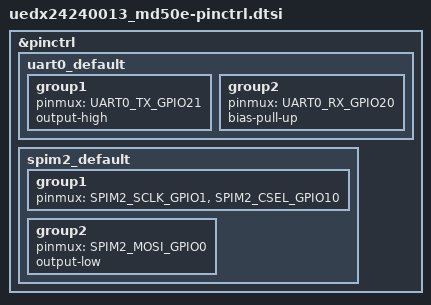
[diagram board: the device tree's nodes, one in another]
/*
 * Copyright (c) 2024 Espressif Systems (Shanghai) Co., Ltd.
 * Copyright (c) 2026 VIEWE Display Co., Ltd.
 *
 * SPDX-License-Identifier: Apache-2.0
 */

#include <zephyr/dt-bindings/pinctrl/esp-pinctrl-common.h>
#include <zephyr/dt-bindings/pinctrl/esp32c3-pinctrl.h>
#include <zephyr/dt-bindings/pinctrl/esp32c3-gpio-sigmap.h>

&pinctrl {
	uart0_default: uart0_default {
		group1 {
			pinmux = <UART0_TX_GPIO21>;
			output-high;
		};

		group2 {
			pinmux = <UART0_RX_GPIO20>;
			bias-pull-up;
		};
	};

	spim2_default: spim2_default {
		group1 {
			pinmux = <SPIM2_SCLK_GPIO1>,
				 <SPIM2_CSEL_GPIO10>;
		};

		group2 {
			pinmux = <SPIM2_MOSI_GPIO0>;
			output-low;
		};
	};
};
